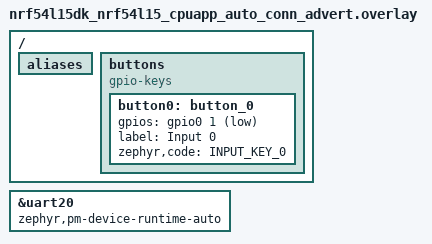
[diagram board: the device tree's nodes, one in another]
/*
 * Copyright (c) 2024 Nordic Semiconductor ASA
 *
 * SPDX-License-Identifier: LicenseRef-Nordic-5-Clause
 */

/ {
	aliases {
		/delete-property/ sw2;
		/delete-property/ sw3;
	};
	/*
	 * Redefine button0 to use RXD0 - P0.01
	 * Thus, when sending character from host, there will be gpio interrupt,
	 * the same as originally triggered by sw0 button.
	 */
	buttons {
		compatible = "gpio-keys";
		button0: button_0 {
			gpios = <&gpio0 1 (GPIO_PULL_UP | GPIO_ACTIVE_LOW)>;
			label = "Input 0";
			zephyr,code = <INPUT_KEY_0>;
		};
	};
};

/delete-node/ &button2;
/delete-node/ &button3;

&uart20 {
	zephyr,pm-device-runtime-auto;
};
